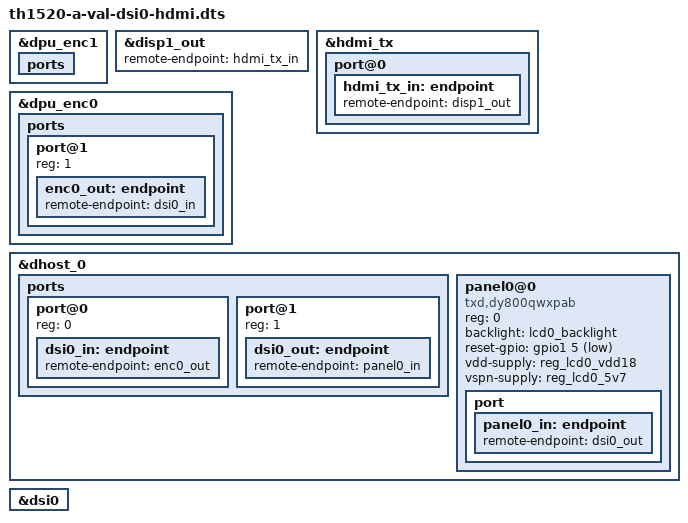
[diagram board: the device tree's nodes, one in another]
/* SPDX-License-Identifier: GPL-2.0 */
/*
 * Copyright (C) 2021 Alibaba Group Holding Limited.
 */

#include "th1520-a-val.dtsi"

&dpu_enc1 {
	ports {
		/delete-node/ port@0;
	};
};

&disp1_out {
	remote-endpoint = <&hdmi_tx_in>;
};

&hdmi_tx {
	status = "okay";

	port@0 {
		/* input */
		hdmi_tx_in: endpoint {
			remote-endpoint = <&disp1_out>;
		};
	};
};

&dpu_enc0 {
	status = "okay";

	ports {
		/* output */
		port@1 {
			reg = <1>;

			enc0_out: endpoint {
				remote-endpoint = <&dsi0_in>;
			};
		};
	};
};

&dhost_0 {
	ports {
		#address-cells = <1>;
		#size-cells = <0>;

		port@0 {
			reg = <0>;

			dsi0_in: endpoint {
				remote-endpoint = <&enc0_out>;
			};
		};

		port@1 {
			reg = <1>;

			dsi0_out: endpoint {
				remote-endpoint = <&panel0_in>;
			};
		};
	};

	panel0@0 {
		compatible = "txd,dy800qwxpab";
		reg = <0>;
		backlight = <&lcd0_backlight>;
		reset-gpio = <&gpio1 5 1>; /* active low */
		vdd-supply = <&reg_lcd0_vdd18>;
		vspn-supply = <&reg_lcd0_5v7>;

		port {
			panel0_in: endpoint {
				remote-endpoint = <&dsi0_out>;
			};
		};
	};
};

&dsi0 {
	status = "okay";
};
